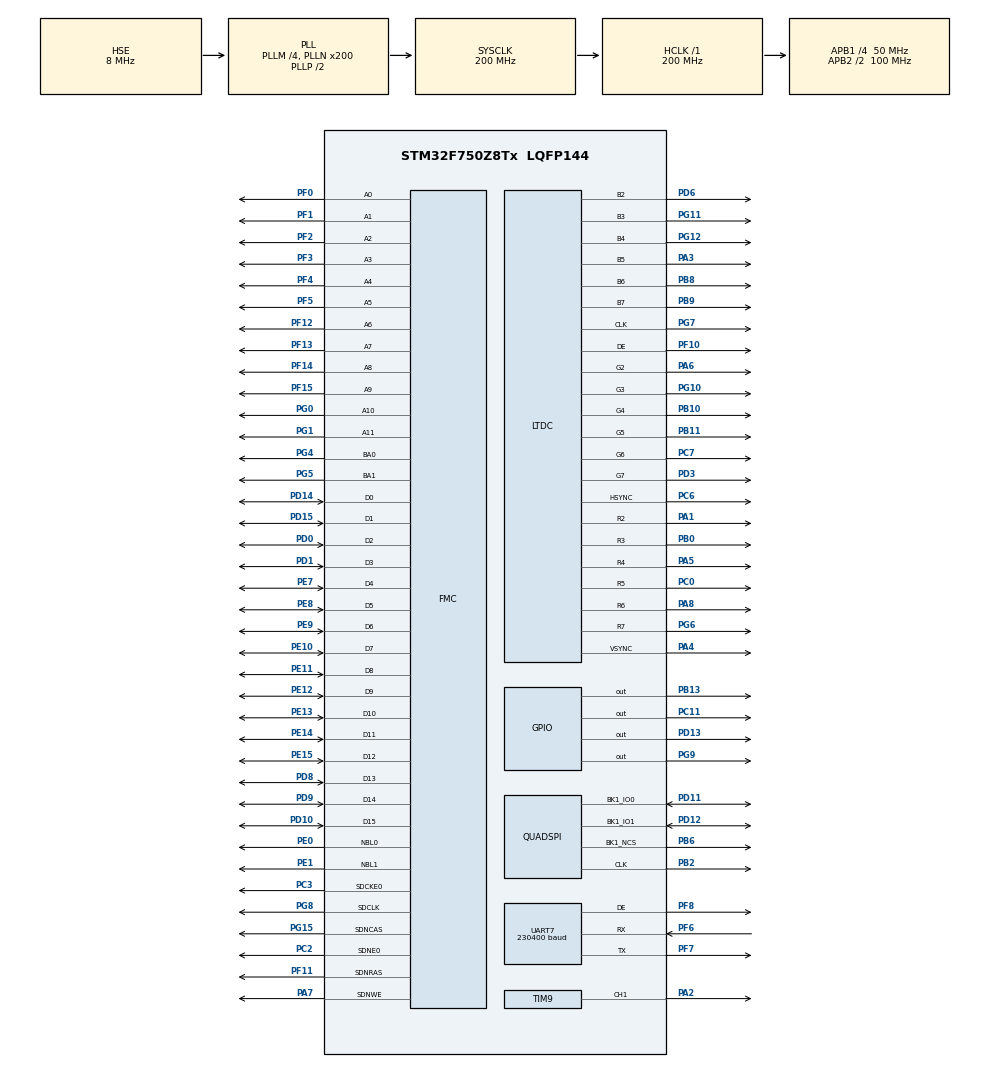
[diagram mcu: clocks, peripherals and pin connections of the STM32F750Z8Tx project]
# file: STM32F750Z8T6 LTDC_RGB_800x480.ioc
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CORTEX_M7.ART_ACCLERATOR_ENABLE=0
CORTEX_M7.AccessPermission-Cortex_Memory_Protection_Unit_Region0_Settings=MPU_REGION_FULL_ACCESS
CORTEX_M7.BaseAddress-Cortex_Memory_Protection_Unit_Region0_Settings=0x20010000
CORTEX_M7.CPU_DCache=Disabled
CORTEX_M7.CPU_ICache=Disabled
CORTEX_M7.Enable-Cortex_Memory_Protection_Unit_Region0_Settings=MPU_REGION_ENABLE
CORTEX_M7.FlashInterface=TCM_Enabled
CORTEX_M7.IsCacheable-Cortex_Memory_Protection_Unit_Region0_Settings=MPU_ACCESS_CACHEABLE
CORTEX_M7.MPU_Control=__NULL
CORTEX_M7.Size-Cortex_Memory_Protection_Unit_Region0_Settings=MPU_REGION_SIZE_256B
DMA2D.AlphaModeForeground=DMA2D_NO_MODIF_ALPHA
DMA2D.ColorMode=DMA2D_OUTPUT_RGB888
DMA2D.Mode=DMA2D_M2M
FMC.CASLatency1=FMC_SDRAM_CAS_LATENCY_2
FMC.ColumnBitsNumber1=FMC_SDRAM_COLUMN_BITS_NUM_9
FMC.ExitSelfRefreshDelay1=7
FMC.LoadToActiveDelay1=2
FMC.RCDDelay1=2
FMC.RPDelay1=2
FMC.RPDelay2=2
FMC.ReadBurst1=FMC_SDRAM_RBURST_ENABLE
FMC.RowCycleDelay1=8
FMC.RowCycleDelay2=8
FMC.SDClockPeriod1=FMC_SDRAM_CLOCK_PERIOD_2
FMC.SelfRefreshTime1=5
FMC.WriteRecoveryTime1=4
LTDC.ActiveW=800
LTDC.Alpha_L0=255
LTDC.BlendingFactor1_L0=LTDC_BLENDING_FACTOR1_PAxCA
LTDC.BlendingFactor2_L0=LTDC_BLENDING_FACTOR2_PAxCA
LTDC.HBP=40
LTDC.HFP=40
LTDC.HSync=48
LTDC.ImageHeight_L0=480
LTDC.ImageWidth_L0=800
LTDC.Layers=0
LTDC.PixelFormat_L0=LTDC_PIXEL_FORMAT_RGB888
LTDC.VBP=31
LTDC.VFP=13
LTDC.VSync=1
LTDC.WindowX1_L0=800
LTDC.WindowY1_L0=480
Mcu.Family=STM32F7
Mcu.Name=STM32F750Z8Tx
Mcu.Package=LQFP144
NVIC.PriorityGroup=NVIC_PRIORITYGROUP_4
NVIC.UART7_IRQn=true\:0\:0\:false\:true\:true\:1\:true\:true
PA1.GPIO_PuPd=GPIO_PULLUP
PA1.GPIO_Speed=GPIO_SPEED_FREQ_HIGH
PA1.Mode=RGB666
PA1.Signal=LTDC_R2
PA13.Mode=JTAG_5_pins
PA13.Signal=SYS_JTMS-SWDIO
PA14.Mode=JTAG_5_pins
PA14.Signal=SYS_JTCK-SWCLK
PA15.Mode=JTAG_5_pins
PA15.Signal=SYS_JTDI
PA2.Signal=S_TIM9_CH1
PA3.GPIO_PuPd=GPIO_PULLUP
PA3.GPIO_Speed=GPIO_SPEED_FREQ_HIGH
PA3.Mode=RGB666
PA3.Signal=LTDC_B5
PA4.GPIO_PuPd=GPIO_PULLUP
PA4.GPIO_Speed=GPIO_SPEED_FREQ_HIGH
PA4.Mode=RGB666
PA4.Signal=LTDC_VSYNC
PA5.GPIO_PuPd=GPIO_PULLUP
PA5.GPIO_Speed=GPIO_SPEED_FREQ_HIGH
PA5.Mode=RGB666
PA5.Signal=LTDC_R4
PA6.GPIO_PuPd=GPIO_PULLUP
PA6.GPIO_Speed=GPIO_SPEED_FREQ_HIGH
PA6.Mode=RGB666
PA6.Signal=LTDC_G2
PA7.GPIO_PuPd=GPIO_PULLUP
PA7.GPIO_Speed_High_Default=GPIO_SPEED_FREQ_VERY_HIGH
PA7.Signal=FMC_SDNWE
PA8.GPIO_PuPd=GPIO_PULLUP
PA8.GPIO_Speed=GPIO_SPEED_FREQ_HIGH
PA8.Mode=RGB666
PA8.Signal=LTDC_R6
PB0.GPIO_PuPd=GPIO_PULLUP
PB0.GPIO_Speed=GPIO_SPEED_FREQ_HIGH
PB0.Mode=RGB666
PB0.Signal=LTDC_R3
PB10.GPIO_PuPd=GPIO_PULLUP
PB10.GPIO_Speed=GPIO_SPEED_FREQ_HIGH
PB10.Mode=RGB666
PB10.Signal=LTDC_G4
PB11.GPIO_PuPd=GPIO_PULLUP
PB11.GPIO_Speed=GPIO_SPEED_FREQ_HIGH
PB11.Mode=RGB666
PB11.Signal=LTDC_G5
PB13.PinState=GPIO_PIN_SET
PB13.Signal=GPIO_Output
PB2.GPIO_PuPd=GPIO_PULLUP
PB2.Mode=Single Bank 1 2IOs
PB2.Signal=QUADSPI_CLK
PB3.Mode=JTAG_5_pins
PB3.Signal=SYS_JTDO-SWO
PB4.Mode=JTAG_5_pins
PB4.Signal=SYS_JTRST
PB6.GPIO_PuPd=GPIO_PULLUP
PB6.Mode=Single Bank 1 2IOs
PB6.Signal=QUADSPI_BK1_NCS
PB8.GPIO_PuPd=GPIO_PULLUP
PB8.GPIO_Speed=GPIO_SPEED_FREQ_HIGH
PB8.Mode=RGB666
PB8.Signal=LTDC_B6
PB9.GPIO_PuPd=GPIO_PULLUP
PB9.GPIO_Speed=GPIO_SPEED_FREQ_HIGH
PB9.Mode=RGB666
PB9.Signal=LTDC_B7
PC0.GPIO_PuPd=GPIO_PULLUP
PC0.GPIO_Speed=GPIO_SPEED_FREQ_HIGH
PC0.Mode=RGB666
PC0.Signal=LTDC_R5
PC11.GPIO_Speed=GPIO_SPEED_FREQ_HIGH
PC11.PinState=GPIO_PIN_SET
PC11.Signal=GPIO_Output
PC2.GPIO_PuPd=GPIO_PULLUP
PC2.GPIO_Speed_High_Default=GPIO_SPEED_FREQ_VERY_HIGH
PC2.Mode=SdramChipSelect1_1
PC2.Signal=FMC_SDNE0
PC3.GPIO_PuPd=GPIO_PULLUP
PC3.GPIO_Speed_High_Default=GPIO_SPEED_FREQ_VERY_HIGH
PC3.Mode=SdramChipSelect1_1
PC3.Signal=FMC_SDCKE0
PC6.GPIO_PuPd=GPIO_PULLUP
PC6.GPIO_Speed=GPIO_SPEED_FREQ_HIGH
PC6.Mode=RGB666
PC6.Signal=LTDC_HSYNC
PC7.GPIO_PuPd=GPIO_PULLUP
PC7.GPIO_Speed=GPIO_SPEED_FREQ_HIGH
PC7.Mode=RGB666
PC7.Signal=LTDC_G6
PD0.GPIO_PuPd=GPIO_PULLUP
PD0.GPIO_Speed_High_Default=GPIO_SPEED_FREQ_VERY_HIGH
PD0.Signal=FMC_D2_DA2
PD1.GPIO_PuPd=GPIO_PULLUP
PD1.GPIO_Speed_High_Default=GPIO_SPEED_FREQ_VERY_HIGH
PD1.Signal=FMC_D3_DA3
PD10.GPIO_PuPd=GPIO_PULLUP
PD10.GPIO_Speed_High_Default=GPIO_SPEED_FREQ_VERY_HIGH
PD10.Signal=FMC_D15_DA15
PD11.GPIO_PuPd=GPIO_PULLUP
PD11.Mode=Single Bank 1 2IOs
PD11.Signal=QUADSPI_BK1_IO0
PD12.GPIO_PuPd=GPIO_PULLUP
PD12.Mode=Single Bank 1 2IOs
PD12.Signal=QUADSPI_BK1_IO1
PD13.PinState=GPIO_PIN_SET
PD13.Signal=GPIO_Output
PD14.GPIO_PuPd=GPIO_PULLUP
PD14.GPIO_Speed_High_Default=GPIO_SPEED_FREQ_VERY_HIGH
PD14.Signal=FMC_D0_DA0
PD15.GPIO_PuPd=GPIO_PULLUP
PD15.GPIO_Speed_High_Default=GPIO_SPEED_FREQ_VERY_HIGH
PD15.Signal=FMC_D1_DA1
PD3.GPIO_PuPd=GPIO_PULLUP
PD3.GPIO_Speed=GPIO_SPEED_FREQ_HIGH
PD3.Mode=RGB666
PD3.Signal=LTDC_G7
PD6.GPIO_PuPd=GPIO_PULLUP
PD6.GPIO_Speed=GPIO_SPEED_FREQ_HIGH
PD6.Mode=RGB666
PD6.Signal=LTDC_B2
PD8.GPIO_PuPd=GPIO_PULLUP
PD8.GPIO_Speed_High_Default=GPIO_SPEED_FREQ_VERY_HIGH
PD8.Signal=FMC_D13_DA13
PD9.GPIO_PuPd=GPIO_PULLUP
PD9.GPIO_Speed_High_Default=GPIO_SPEED_FREQ_VERY_HIGH
PD9.Signal=FMC_D14_DA14
PE0.GPIO_PuPd=GPIO_PULLUP
PE0.GPIO_Speed_High_Default=GPIO_SPEED_FREQ_VERY_HIGH
PE0.Signal=FMC_NBL0
PE1.GPIO_PuPd=GPIO_PULLUP
PE1.GPIO_Speed_High_Default=GPIO_SPEED_FREQ_VERY_HIGH
PE1.Signal=FMC_NBL1
PE10.GPIO_PuPd=GPIO_PULLUP
PE10.GPIO_Speed_High_Default=GPIO_SPEED_FREQ_VERY_HIGH
PE10.Signal=FMC_D7_DA7
PE11.GPIO_PuPd=GPIO_PULLUP
PE11.GPIO_Speed_High_Default=GPIO_SPEED_FREQ_VERY_HIGH
PE11.Signal=FMC_D8_DA8
PE12.GPIO_PuPd=GPIO_PULLUP
PE12.GPIO_Speed_High_Default=GPIO_SPEED_FREQ_VERY_HIGH
PE12.Signal=FMC_D9_DA9
PE13.GPIO_PuPd=GPIO_PULLUP
PE13.GPIO_Speed_High_Default=GPIO_SPEED_FREQ_VERY_HIGH
PE13.Signal=FMC_D10_DA10
PE14.GPIO_PuPd=GPIO_PULLUP
PE14.GPIO_Speed_High_Default=GPIO_SPEED_FREQ_VERY_HIGH
PE14.Signal=FMC_D11_DA11
PE15.GPIO_PuPd=GPIO_PULLUP
PE15.GPIO_Speed_High_Default=GPIO_SPEED_FREQ_VERY_HIGH
PE15.Signal=FMC_D12_DA12
PE7.GPIO_PuPd=GPIO_PULLUP
PE7.GPIO_Speed_High_Default=GPIO_SPEED_FREQ_VERY_HIGH
PE7.Signal=FMC_D4_DA4
PE8.GPIO_PuPd=GPIO_PULLUP
PE8.GPIO_Speed_High_Default=GPIO_SPEED_FREQ_VERY_HIGH
PE8.Signal=FMC_D5_DA5
PE9.GPIO_PuPd=GPIO_PULLUP
PE9.GPIO_Speed_High_Default=GPIO_SPEED_FREQ_VERY_HIGH
PE9.Signal=FMC_D6_DA6
PF0.GPIO_PuPd=GPIO_PULLUP
PF0.GPIO_Speed_High_Default=GPIO_SPEED_FREQ_VERY_HIGH
PF0.Signal=FMC_A0
PF1.GPIO_PuPd=GPIO_PULLUP
PF1.GPIO_Speed_High_Default=GPIO_SPEED_FREQ_VERY_HIGH
PF1.Signal=FMC_A1
PF10.GPIO_PuPd=GPIO_PULLUP
PF10.GPIO_Speed=GPIO_SPEED_FREQ_HIGH
PF10.Mode=RGB666
PF10.Signal=LTDC_DE
PF11.GPIO_PuPd=GPIO_PULLUP
PF11.GPIO_Speed_High_Default=GPIO_SPEED_FREQ_VERY_HIGH
PF11.Signal=FMC_SDNRAS
PF12.GPIO_PuPd=GPIO_PULLUP
PF12.GPIO_Speed_High_Default=GPIO_SPEED_FREQ_VERY_HIGH
PF12.Signal=FMC_A6
PF13.GPIO_PuPd=GPIO_PULLUP
PF13.GPIO_Speed_High_Default=GPIO_SPEED_FREQ_VERY_HIGH
PF13.Signal=FMC_A7
PF14.GPIO_PuPd=GPIO_PULLUP
PF14.GPIO_Speed_High_Default=GPIO_SPEED_FREQ_VERY_HIGH
PF14.Signal=FMC_A8
PF15.GPIO_PuPd=GPIO_PULLUP
PF15.GPIO_Speed_High_Default=GPIO_SPEED_FREQ_VERY_HIGH
PF15.Signal=FMC_A9
PF2.GPIO_PuPd=GPIO_PULLUP
PF2.GPIO_Speed_High_Default=GPIO_SPEED_FREQ_VERY_HIGH
PF2.Signal=FMC_A2
PF3.GPIO_PuPd=GPIO_PULLUP
PF3.GPIO_Speed_High_Default=GPIO_SPEED_FREQ_VERY_HIGH
PF3.Signal=FMC_A3
PF4.GPIO_PuPd=GPIO_PULLUP
PF4.GPIO_Speed_High_Default=GPIO_SPEED_FREQ_VERY_HIGH
PF4.Signal=FMC_A4
PF5.GPIO_PuPd=GPIO_PULLUP
PF5.GPIO_Speed_High_Default=GPIO_SPEED_FREQ_VERY_HIGH
PF5.Signal=FMC_A5
PF6.Mode=Asynchronous
PF6.Signal=UART7_RX
PF7.Mode=Asynchronous
PF7.Signal=UART7_TX
PF8.Mode=Hardware Flow Control (RS485)
PF8.Signal=UART7_DE
PG0.GPIO_PuPd=GPIO_PULLUP
PG0.GPIO_Speed_High_Default=GPIO_SPEED_FREQ_VERY_HIGH
PG0.Signal=FMC_A10
PG1.GPIO_PuPd=GPIO_PULLUP
PG1.GPIO_Speed_High_Default=GPIO_SPEED_FREQ_VERY_HIGH
PG1.Signal=FMC_A11
PG10.GPIO_PuPd=GPIO_PULLUP
PG10.GPIO_Speed=GPIO_SPEED_FREQ_HIGH
PG10.Mode=RGB666
PG10.Signal=LTDC_G3
PG11.GPIO_PuPd=GPIO_PULLUP
PG11.GPIO_Speed=GPIO_SPEED_FREQ_HIGH
PG11.Mode=RGB666
PG11.Signal=LTDC_B3
PG12.GPIO_PuPd=GPIO_PULLUP
PG12.GPIO_Speed=GPIO_SPEED_FREQ_HIGH
PG12.Mode=RGB666
PG12.Signal=LTDC_B4
PG15.GPIO_PuPd=GPIO_PULLUP
PG15.GPIO_Speed_High_Default=GPIO_SPEED_FREQ_VERY_HIGH
PG15.Signal=FMC_SDNCAS
PG4.GPIO_PuPd=GPIO_PULLUP
PG4.GPIO_Speed_High_Default=GPIO_SPEED_FREQ_VERY_HIGH
PG4.Signal=FMC_A14_BA0
PG5.GPIO_PuPd=GPIO_PULLUP
PG5.GPIO_Speed_High_Default=GPIO_SPEED_FREQ_VERY_HIGH
PG5.Signal=FMC_A15_BA1
PG6.GPIO_PuPd=GPIO_PULLUP
PG6.GPIO_Speed=GPIO_SPEED_FREQ_HIGH
PG6.Mode=RGB666
PG6.Signal=LTDC_R7
PG7.GPIO_PuPd=GPIO_PULLUP
PG7.GPIO_Speed=GPIO_SPEED_FREQ_HIGH
PG7.Mode=RGB666
PG7.Signal=LTDC_CLK
PG8.GPIO_PuPd=GPIO_PULLUP
PG8.GPIO_Speed_High_Default=GPIO_SPEED_FREQ_VERY_HIGH
PG8.Signal=FMC_SDCLK
PG9.GPIO_PuPd=GPIO_NOPULL
PG9.PinState=GPIO_PIN_SET
PG9.Signal=GPIO_Output
PH0/OSC_IN.Mode=HSE-External-Oscillator
PH0/OSC_IN.Signal=RCC_OSC_IN
PH1/OSC_OUT.Mode=HSE-External-Oscillator
PH1/OSC_OUT.Signal=RCC_OSC_OUT
ProjectManager.HeapSize=0x200
ProjectManager.StackSize=0x400
ProjectManager.TargetToolchain=MDK-ARM V5.27
QUADSPI.ClockPrescaler=4
QUADSPI.FlashSize=23
RCC.AHBFreq_Value=200000000
RCC.APB1CLKDivider=RCC_HCLK_DIV4
RCC.APB1Freq_Value=50000000
RCC.APB1TimFreq_Value=100000000
RCC.APB2CLKDivider=RCC_HCLK_DIV2
RCC.APB2Freq_Value=100000000
RCC.APB2TimFreq_Value=200000000
RCC.CortexFreq_Value=200000000
RCC.HCLKFreq_Value=200000000
RCC.HSE_VALUE=8000000
RCC.HSI_VALUE=16000000
RCC.LSE_VALUE=32768
RCC.PLLM=4
RCC.PLLN=200
RCC.PLLSAIN=60
RCC.PLLSourceVirtual=RCC_PLLSOURCE_HSE
RCC.SYSCLKFreq_VALUE=200000000
RCC.SYSCLKSource=RCC_SYSCLKSOURCE_PLLCLK
RCC.USBFreq_Value=200000000
RCC.VCOOutputFreq_Value=400000000
SH.FMC_A0.0=FMC_A0,12b-sda1
SH.FMC_A1.0=FMC_A1,12b-sda1
SH.FMC_A10.0=FMC_A10,12b-sda1
SH.FMC_A11.0=FMC_A11,12b-sda1
SH.FMC_A14_BA0.0=FMC_BA0,FourSdramBanks1
SH.FMC_A15_BA1.0=FMC_BA1,FourSdramBanks1
SH.FMC_A2.0=FMC_A2,12b-sda1
SH.FMC_A3.0=FMC_A3,12b-sda1
SH.FMC_A4.0=FMC_A4,12b-sda1
SH.FMC_A5.0=FMC_A5,12b-sda1
SH.FMC_A6.0=FMC_A6,12b-sda1
SH.FMC_A7.0=FMC_A7,12b-sda1
SH.FMC_A8.0=FMC_A8,12b-sda1
SH.FMC_A9.0=FMC_A9,12b-sda1
SH.FMC_D0_DA0.0=FMC_D0,sd-16b-d1
SH.FMC_D10_DA10.0=FMC_D10,sd-16b-d1
SH.FMC_D11_DA11.0=FMC_D11,sd-16b-d1
SH.FMC_D12_DA12.0=FMC_D12,sd-16b-d1
SH.FMC_D13_DA13.0=FMC_D13,sd-16b-d1
SH.FMC_D14_DA14.0=FMC_D14,sd-16b-d1
SH.FMC_D15_DA15.0=FMC_D15,sd-16b-d1
SH.FMC_D1_DA1.0=FMC_D1,sd-16b-d1
SH.FMC_D2_DA2.0=FMC_D2,sd-16b-d1
SH.FMC_D3_DA3.0=FMC_D3,sd-16b-d1
SH.FMC_D4_DA4.0=FMC_D4,sd-16b-d1
SH.FMC_D5_DA5.0=FMC_D5,sd-16b-d1
SH.FMC_D6_DA6.0=FMC_D6,sd-16b-d1
SH.FMC_D7_DA7.0=FMC_D7,sd-16b-d1
SH.FMC_D8_DA8.0=FMC_D8,sd-16b-d1
SH.FMC_D9_DA9.0=FMC_D9,sd-16b-d1
SH.FMC_NBL0.0=FMC_NBL0,Sd2ByteEnable1
SH.FMC_NBL1.0=FMC_NBL1,Sd2ByteEnable1
SH.FMC_SDCLK.0=FMC_SDCLK,12b-sda1
SH.FMC_SDNCAS.0=FMC_SDNCAS,12b-sda1
SH.FMC_SDNRAS.0=FMC_SDNRAS,12b-sda1
SH.FMC_SDNWE.0=FMC_SDNWE,12b-sda1
SH.S_TIM9_CH1.0=TIM9_CH1,PWM Generation1 CH1
TIM9.Channel-PWM\ Generation1\ CH1=TIM_CHANNEL_1
TIM9.Period=100
TIM9.Prescaler=2000
TIM9.Pulse-PWM\ Generation1\ CH1=50
UART7.BaudRate=230400
UART7.UART_DEAssertionTime=31
VP_DMA2D_VS_DMA2D.Mode=DMA2D_Activate
board=custom

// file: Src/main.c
/* USER CODE BEGIN Header */
/**
  ******************************************************************************
  * @file           : main.c
  * @brief          : Main program body
  ******************************************************************************
  * @attention
  *
  * <h2><center>&copy; Copyright (c) 2019 STMicroelectronics.
  * All rights reserved.</center></h2>
  *
  * This software component is licensed by ST under BSD 3-Clause license,
  * the "License"; You may not use this file except in compliance with the
  * License. You may obtain a copy of the License at:
  *                        opensource.org/licenses/BSD-3-Clause
  *
  ******************************************************************************
  */
/* USER CODE END Header */

#include "main.h"

/* USER CODE BEGIN Includes */
#include "quad_spi.h"
#include "xmodem_uart.h"
#include "fonts.h"
/* USER CODE END Includes */

DMA2D_HandleTypeDef hdma2d;

LTDC_HandleTypeDef hltdc;

QSPI_HandleTypeDef hqspi;

TIM_HandleTypeDef htim9;

UART_HandleTypeDef huart7;

SDRAM_HandleTypeDef hsdram1;

/* USER CODE BEGIN PV */
FMC_SDRAM_CommandTypeDef command;
/* USER CODE END PV */

void SystemClock_Config(void);
static void MX_GPIO_Init(void);
static void MX_LTDC_Init(void);
static void MX_FMC_Init(void);
static void MX_DMA2D_Init(void);
static void MX_UART7_Init(void);
static void MX_QUADSPI_Init(void);
static void MX_TIM9_Init(void);
static void MX_NVIC_Init(void);
/* USER CODE BEGIN PFP */
static void BSP_SDRAM_Initialization_Sequence(SDRAM_HandleTypeDef *hsdram, FMC_SDRAM_CommandTypeDef *Command);

__IO uint8_t flag_end_of_transmit = 0;
/* USER CODE END PFP */

int main(void)
{

  /* MCU Configuration--------------------------------------------------------*/

  /* Reset of all peripherals, Initializes the Flash interface and the Systick. */
  HAL_Init();

  /* Configure the system clock */
  SystemClock_Config();

  /* Initialize all configured peripherals */
  MX_GPIO_Init();
  MX_LTDC_Init();
  MX_FMC_Init();
  MX_DMA2D_Init();
  MX_UART7_Init();
  MX_QUADSPI_Init();
  MX_TIM9_Init();

  /* Initialize interrupts */
  MX_NVIC_Init();
  /* USER CODE BEGIN 2 */
  //Program the SDRAM external device
  BSP_SDRAM_Initialization_Sequence(&hsdram1, &command);
  //UART Interrupt RX enable
  //UART7->CR1 |= USART_ISR_RXNE;

  HAL_LTDC_SetAddress(&hltdc,(uint32_t) SDRAM_BANK_ADDR,0);

  //FLASH to SDRAM
  QspiReadData(0, 800 * 480 * 3, (uint8_t*)SDRAM_BANK_ADDR);
	for(uint32_t i = 0; i < 1000; i += 4)
          {

            *(__IO uint32_t*) (SDRAM_BANK_ADDR + i) = 0x0;

          }

  //brightness %
  TIM9->CCR1 = 100;
  HAL_TIM_PWM_Start(&htim9, TIM_CHANNEL_1);

  HAL_DMA2D_ConfigDeadTime(&hdma2d, 100);
  HAL_DMA2D_EnableDeadTime(&hdma2d);

  QspiReadID();
  QspiReadID();
  /* USER CODE END 2 */

  /* Infinite loop */
  /* USER CODE BEGIN WHILE */
  while (1)
  {
    //test SDRAM W25Q64JV
    /*uint8_t spi_data[4] = {0};
    spi_data[0] = 0xAA;
    spi_data[1] = 0x12;
	  BSP_QSPI_Erase_Sector(0);
    QspiWriteData(0, 4, spi_data);
    spi_data[0] = 0x55;
    QspiReadData(0, 4, spi_data);*/

    //по окончанию передачи по xmodem
    //write in FLASH from SDRAM
    if(flag_end_of_transmit) {
      //0 - start addr, 20 * 64KB = 1,28MB
      BSP_QSPI_Erase_Block_64KB(0, 20);
	  BSP_QSPI_Erase_Block_64KB(0, 20);
      for(uint32_t i = 0; i < 800 * 480 * 3;) {
        QspiWriteData(i, 256, (uint8_t*)(SDRAM_BANK_ADDR + i)); //write in flash memory	(256 bytes max in one transaction)
        i += 256;
      }
      flag_end_of_transmit = 0;
    }
/*
    //draw_font8x14("16.01.20, 14:40", 332, 389, 0x00FFFFFF, 0x00585D73);
    static uint8_t pos = '0';
    //draw_font8x14((char *)&(pos), 336, 408, 0x00FFFFFF, 0x00585D73);
    pos++;
    if(pos > '9') pos = '0';
	*/
    /* USER CODE END WHILE */

    /* USER CODE BEGIN 3 */
    //uart xmodem
    uart_xmodem_receive();
  }
  /* USER CODE END 3 */
}

void SystemClock_Config(void)
{
  RCC_OscInitTypeDef RCC_OscInitStruct = {0};
  RCC_ClkInitTypeDef RCC_ClkInitStruct = {0};
  RCC_PeriphCLKInitTypeDef PeriphClkInitStruct = {0};

  /** Configure the main internal regulator output voltage
  */
  __HAL_RCC_PWR_CLK_ENABLE();
  __HAL_PWR_VOLTAGESCALING_CONFIG(PWR_REGULATOR_VOLTAGE_SCALE1);
  /** Initializes the CPU, AHB and APB busses clocks
  */
  RCC_OscInitStruct.OscillatorType = RCC_OSCILLATORTYPE_HSE;
  RCC_OscInitStruct.HSEState = RCC_HSE_ON;
  RCC_OscInitStruct.PLL.PLLState = RCC_PLL_ON;
  RCC_OscInitStruct.PLL.PLLSource = RCC_PLLSOURCE_HSE;
  RCC_OscInitStruct.PLL.PLLM = 4;
  RCC_OscInitStruct.PLL.PLLN = 200;
  RCC_OscInitStruct.PLL.PLLP = RCC_PLLP_DIV2;
  RCC_OscInitStruct.PLL.PLLQ = 2;
  if (HAL_RCC_OscConfig(&RCC_OscInitStruct) != HAL_OK)
  {
    Error_Handler();
  }
  /** Activate the Over-Drive mode
  */
  if (HAL_PWREx_EnableOverDrive() != HAL_OK)
  {
    Error_Handler();
  }
  /** Initializes the CPU, AHB and APB busses clocks
  */
  RCC_ClkInitStruct.ClockType = RCC_CLOCKTYPE_HCLK|RCC_CLOCKTYPE_SYSCLK
                              |RCC_CLOCKTYPE_PCLK1|RCC_CLOCKTYPE_PCLK2;
  RCC_ClkInitStruct.SYSCLKSource = RCC_SYSCLKSOURCE_PLLCLK;
  RCC_ClkInitStruct.AHBCLKDivider = RCC_SYSCLK_DIV1;
  RCC_ClkInitStruct.APB1CLKDivider = RCC_HCLK_DIV4;
  RCC_ClkInitStruct.APB2CLKDivider = RCC_HCLK_DIV2;

  if (HAL_RCC_ClockConfig(&RCC_ClkInitStruct, FLASH_LATENCY_6) != HAL_OK)
  {
    Error_Handler();
  }
  PeriphClkInitStruct.PeriphClockSelection = RCC_PERIPHCLK_LTDC|RCC_PERIPHCLK_UART7;
  PeriphClkInitStruct.PLLSAI.PLLSAIN = 60;
  PeriphClkInitStruct.PLLSAI.PLLSAIR = 2;
  PeriphClkInitStruct.PLLSAI.PLLSAIQ = 2;
  PeriphClkInitStruct.PLLSAI.PLLSAIP = RCC_PLLSAIP_DIV2;
  PeriphClkInitStruct.PLLSAIDivQ = 1;
  PeriphClkInitStruct.PLLSAIDivR = RCC_PLLSAIDIVR_2;
  PeriphClkInitStruct.Uart7ClockSelection = RCC_UART7CLKSOURCE_PCLK1;
  if (HAL_RCCEx_PeriphCLKConfig(&PeriphClkInitStruct) != HAL_OK)
  {
    Error_Handler();
  }
}

/**
  * @brief NVIC Configuration.
  * @retval None
  */
static void MX_NVIC_Init(void)
{
  /* UART7_IRQn interrupt configuration */
  HAL_NVIC_SetPriority(UART7_IRQn, 0, 0);
  HAL_NVIC_EnableIRQ(UART7_IRQn);
}

static void MX_DMA2D_Init(void)
{

  hdma2d.Instance = DMA2D;
  hdma2d.Init.Mode = DMA2D_M2M;
  hdma2d.Init.ColorMode = DMA2D_OUTPUT_RGB888;
  hdma2d.Init.OutputOffset = 0;
  hdma2d.LayerCfg[1].InputOffset = 0;
  hdma2d.LayerCfg[1].InputColorMode = DMA2D_INPUT_RGB888;
  hdma2d.LayerCfg[1].AlphaMode = DMA2D_NO_MODIF_ALPHA;
  hdma2d.LayerCfg[1].InputAlpha = 0;
  if (HAL_DMA2D_Init(&hdma2d) != HAL_OK)
  {
    Error_Handler();
  }
  if (HAL_DMA2D_ConfigLayer(&hdma2d, 1) != HAL_OK)
  {
    Error_Handler();
  }

}

static void MX_LTDC_Init(void)
{

  LTDC_LayerCfgTypeDef pLayerCfg = {0};

  hltdc.Instance = LTDC;
  hltdc.Init.HSPolarity = LTDC_HSPOLARITY_AL;
  hltdc.Init.VSPolarity = LTDC_VSPOLARITY_AL;
  hltdc.Init.DEPolarity = LTDC_DEPOLARITY_AL;
  hltdc.Init.PCPolarity = LTDC_PCPOLARITY_IPC;
  hltdc.Init.HorizontalSync = 47;
  hltdc.Init.VerticalSync = 0;
  hltdc.Init.AccumulatedHBP = 87;
  hltdc.Init.AccumulatedVBP = 31;
  hltdc.Init.AccumulatedActiveW = 887;
  hltdc.Init.AccumulatedActiveH = 511;
  hltdc.Init.TotalWidth = 927;
  hltdc.Init.TotalHeigh = 524;
  hltdc.Init.Backcolor.Blue = 0;
  hltdc.Init.Backcolor.Green = 0;
  hltdc.Init.Backcolor.Red = 0;
  if (HAL_LTDC_Init(&hltdc) != HAL_OK)
  {
    Error_Handler();
  }
  pLayerCfg.WindowX0 = 0;
  pLayerCfg.WindowX1 = 800;
  pLayerCfg.WindowY0 = 0;
  pLayerCfg.WindowY1 = 480;
  pLayerCfg.PixelFormat = LTDC_PIXEL_FORMAT_RGB888;
  pLayerCfg.Alpha = 255;
  pLayerCfg.Alpha0 = 0;
  pLayerCfg.BlendingFactor1 = LTDC_BLENDING_FACTOR1_PAxCA;
  pLayerCfg.BlendingFactor2 = LTDC_BLENDING_FACTOR2_PAxCA;
  pLayerCfg.FBStartAdress = 0;
  pLayerCfg.ImageWidth = 800;
  pLayerCfg.ImageHeight = 480;
  pLayerCfg.Backcolor.Blue = 0;
  pLayerCfg.Backcolor.Green = 0;
  pLayerCfg.Backcolor.Red = 0;
  if (HAL_LTDC_ConfigLayer(&hltdc, &pLayerCfg, 0) != HAL_OK)
  {
    Error_Handler();
  }

}

static void MX_QUADSPI_Init(void)
{

  /* QUADSPI parameter configuration*/
  hqspi.Instance = QUADSPI;
  hqspi.Init.ClockPrescaler = 4;
  hqspi.Init.FifoThreshold = 1;
  hqspi.Init.SampleShifting = QSPI_SAMPLE_SHIFTING_NONE;
  hqspi.Init.FlashSize = 23;
  hqspi.Init.ChipSelectHighTime = QSPI_CS_HIGH_TIME_1_CYCLE;
  hqspi.Init.ClockMode = QSPI_CLOCK_MODE_0;
  hqspi.Init.FlashID = QSPI_FLASH_ID_1;
  hqspi.Init.DualFlash = QSPI_DUALFLASH_DISABLE;
  if (HAL_QSPI_Init(&hqspi) != HAL_OK)
  {
    Error_Handler();
  }

}

static void MX_TIM9_Init(void)
{

  TIM_OC_InitTypeDef sConfigOC = {0};

  htim9.Instance = TIM9;
  htim9.Init.Prescaler = 2000;
  htim9.Init.CounterMode = TIM_COUNTERMODE_UP;
  htim9.Init.Period = 100;
  htim9.Init.ClockDivision = TIM_CLOCKDIVISION_DIV1;
  htim9.Init.AutoReloadPreload = TIM_AUTORELOAD_PRELOAD_DISABLE;
  if (HAL_TIM_PWM_Init(&htim9) != HAL_OK)
  {
    Error_Handler();
  }
  sConfigOC.OCMode = TIM_OCMODE_PWM1;
  sConfigOC.Pulse = 50;
  sConfigOC.OCPolarity = TIM_OCPOLARITY_HIGH;
  sConfigOC.OCFastMode = TIM_OCFAST_DISABLE;
  if (HAL_TIM_PWM_ConfigChannel(&htim9, &sConfigOC, TIM_CHANNEL_1) != HAL_OK)
  {
    Error_Handler();
  }
  HAL_TIM_MspPostInit(&htim9);

}

static void MX_UART7_Init(void)
{

  huart7.Instance = UART7;
  huart7.Init.BaudRate = 230400;
  huart7.Init.WordLength = UART_WORDLENGTH_8B;
  huart7.Init.StopBits = UART_STOPBITS_1;
  huart7.Init.Parity = UART_PARITY_NONE;
  huart7.Init.Mode = UART_MODE_TX_RX;
  huart7.Init.HwFlowCtl = UART_HWCONTROL_NONE;
  huart7.Init.OverSampling = UART_OVERSAMPLING_16;
  huart7.Init.OneBitSampling = UART_ONE_BIT_SAMPLE_DISABLE;
  huart7.AdvancedInit.AdvFeatureInit = UART_ADVFEATURE_NO_INIT;
  if (HAL_RS485Ex_Init(&huart7, UART_DE_POLARITY_HIGH, 31, 0) != HAL_OK)
  {
    Error_Handler();
  }

}

/* FMC initialization function */
static void MX_FMC_Init(void)
{

  FMC_SDRAM_TimingTypeDef SdramTiming = {0};

  /** Perform the SDRAM1 memory initialization sequence
  */
  hsdram1.Instance = FMC_SDRAM_DEVICE;
  /* hsdram1.Init */
  hsdram1.Init.SDBank = FMC_SDRAM_BANK1;
  hsdram1.Init.ColumnBitsNumber = FMC_SDRAM_COLUMN_BITS_NUM_9;
  hsdram1.Init.RowBitsNumber = FMC_SDRAM_ROW_BITS_NUM_12;
  hsdram1.Init.MemoryDataWidth = FMC_SDRAM_MEM_BUS_WIDTH_16;
  hsdram1.Init.InternalBankNumber = FMC_SDRAM_INTERN_BANKS_NUM_4;
  hsdram1.Init.CASLatency = FMC_SDRAM_CAS_LATENCY_2;
  hsdram1.Init.WriteProtection = FMC_SDRAM_WRITE_PROTECTION_DISABLE;
  hsdram1.Init.SDClockPeriod = FMC_SDRAM_CLOCK_PERIOD_2;
  hsdram1.Init.ReadBurst = FMC_SDRAM_RBURST_ENABLE;
  hsdram1.Init.ReadPipeDelay = FMC_SDRAM_RPIPE_DELAY_0;
  /* SdramTiming */
  SdramTiming.LoadToActiveDelay = 2;
  SdramTiming.ExitSelfRefreshDelay = 7;
  SdramTiming.SelfRefreshTime = 5;
  SdramTiming.RowCycleDelay = 8;
  SdramTiming.WriteRecoveryTime = 4;
  SdramTiming.RPDelay = 2;
  SdramTiming.RCDDelay = 2;

  if (HAL_SDRAM_Init(&hsdram1, &SdramTiming) != HAL_OK)
  {
    Error_Handler( );
  }

}

static void MX_GPIO_Init(void)
{
  GPIO_InitTypeDef GPIO_InitStruct = {0};

  /* GPIO Ports Clock Enable */
  __HAL_RCC_GPIOF_CLK_ENABLE();
  __HAL_RCC_GPIOH_CLK_ENABLE();
  __HAL_RCC_GPIOC_CLK_ENABLE();
  __HAL_RCC_GPIOA_CLK_ENABLE();
  __HAL_RCC_GPIOB_CLK_ENABLE();
  __HAL_RCC_GPIOG_CLK_ENABLE();
  __HAL_RCC_GPIOE_CLK_ENABLE();
  __HAL_RCC_GPIOD_CLK_ENABLE();

  /*Configure GPIO pin Output Level */
  HAL_GPIO_WritePin(GPIOB, GPIO_PIN_13, GPIO_PIN_SET);

  /*Configure GPIO pin Output Level */
  HAL_GPIO_WritePin(GPIOD, GPIO_PIN_13, GPIO_PIN_SET);

  /*Configure GPIO pin Output Level */
  HAL_GPIO_WritePin(GPIOC, GPIO_PIN_11, GPIO_PIN_SET);

  /*Configure GPIO pin Output Level */
  HAL_GPIO_WritePin(GPIOG, GPIO_PIN_9, GPIO_PIN_SET);

  /*Configure GPIO pin : PB13 */
  GPIO_InitStruct.Pin = GPIO_PIN_13;
  GPIO_InitStruct.Mode = GPIO_MODE_OUTPUT_PP;
  GPIO_InitStruct.Pull = GPIO_NOPULL;
  GPIO_InitStruct.Speed = GPIO_SPEED_FREQ_LOW;
  HAL_GPIO_Init(GPIOB, &GPIO_InitStruct);

  /*Configure GPIO pin : PD13 */
  GPIO_InitStruct.Pin = GPIO_PIN_13;
  GPIO_InitStruct.Mode = GPIO_MODE_OUTPUT_PP;
  GPIO_InitStruct.Pull = GPIO_NOPULL;
  GPIO_InitStruct.Speed = GPIO_SPEED_FREQ_LOW;
  HAL_GPIO_Init(GPIOD, &GPIO_InitStruct);

  /*Configure GPIO pin : PC11 */
  GPIO_InitStruct.Pin = GPIO_PIN_11;
  GPIO_InitStruct.Mode = GPIO_MODE_OUTPUT_PP;
  GPIO_InitStruct.Pull = GPIO_NOPULL;
  GPIO_InitStruct.Speed = GPIO_SPEED_FREQ_HIGH;
  HAL_GPIO_Init(GPIOC, &GPIO_InitStruct);

  /*Configure GPIO pin : PG9 */
  GPIO_InitStruct.Pin = GPIO_PIN_9;
  GPIO_InitStruct.Mode = GPIO_MODE_OUTPUT_PP;
  GPIO_InitStruct.Pull = GPIO_NOPULL;
  GPIO_InitStruct.Speed = GPIO_SPEED_FREQ_LOW;
  HAL_GPIO_Init(GPIOG, &GPIO_InitStruct);

}

/* USER CODE BEGIN 4 */
/**
  * @brief  Perform the SDRAM external memory initialization sequence
  * @param  hsdram: SDRAM handle
  * @param  Command: Pointer to SDRAM command structure
  * @retval None
  */
static void BSP_SDRAM_Initialization_Sequence(SDRAM_HandleTypeDef *hsdram, FMC_SDRAM_CommandTypeDef *Command)
{
  __IO uint32_t tmpmrd =0;
  /* Step 3:  Configure a clock configuration enable command */
  Command->CommandMode = FMC_SDRAM_CMD_CLK_ENABLE;
  Command->CommandTarget = FMC_SDRAM_CMD_TARGET_BANK1;
  Command->AutoRefreshNumber = 1;
  Command->ModeRegisterDefinition = 0;
  /* Send the command */
  HAL_SDRAM_SendCommand(hsdram, Command, SDRAM_TIMEOUT);

  /* Step 4: Insert 100 us minimum delay */
  /* Inserted delay is equal to 1 ms due to systick time base unit (ms) */
  HAL_Delay(1);

  /* Step 5: Configure a PALL (precharge all) command */
  Command->CommandMode = FMC_SDRAM_CMD_PALL;
  Command->CommandTarget = FMC_SDRAM_CMD_TARGET_BANK1;
  Command->AutoRefreshNumber = 1;
  Command->ModeRegisterDefinition = 0;
  /* Send the command */
  HAL_SDRAM_SendCommand(hsdram, Command, SDRAM_TIMEOUT);

  /* Step 6 : Configure a Auto-Refresh command */
  Command->CommandMode = FMC_SDRAM_CMD_AUTOREFRESH_MODE;
  Command->CommandTarget = FMC_SDRAM_CMD_TARGET_BANK1;
  Command->AutoRefreshNumber = 8;
  Command->ModeRegisterDefinition = 0;
  /* Send the command */
  HAL_SDRAM_SendCommand(hsdram, Command, SDRAM_TIMEOUT);

  /* Step 7: Program the external memory mode register */
  tmpmrd = (uint32_t)SDRAM_MODEREG_BURST_LENGTH_1          |
                     SDRAM_MODEREG_BURST_TYPE_SEQUENTIAL   |
                     SDRAM_MODEREG_CAS_LATENCY_2           |
                     SDRAM_MODEREG_OPERATING_MODE_STANDARD |
                     SDRAM_MODEREG_WRITEBURST_MODE_SINGLE;

  Command->CommandMode = FMC_SDRAM_CMD_LOAD_MODE;
  Command->CommandTarget = FMC_SDRAM_CMD_TARGET_BANK1;
  Command->AutoRefreshNumber = 1;
  Command->ModeRegisterDefinition = tmpmrd;
  /* Send the command */
  HAL_SDRAM_SendCommand(hsdram, Command, SDRAM_TIMEOUT);

  /* Step 8: Set the refresh rate counter */
  /* (15.62 us x Freq) - 20 */
  /* Set the device refresh counter */
  //hsdram->Instance->SDRTR |= ((uint32_t)((1292)<< 1));
  hsdram->Instance->SDRTR = ((uint32_t)(64000*65/4096-20) << 1);
}
/* USER CODE END 4 */

void Error_Handler(void)
{
}

/************************ (C) COPYRIGHT STMicroelectronics *****END OF FILE****/
